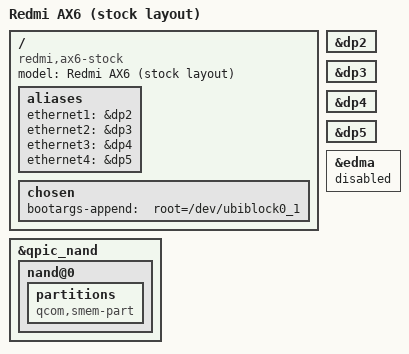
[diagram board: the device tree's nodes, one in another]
// SPDX-License-Identifier: GPL-2.0-or-later OR MIT

/dts-v1/;

#include "ipq8071-ax6.dts"

/ {
	model = "Redmi AX6 (stock layout)";
	compatible = "redmi,ax6-stock", "qcom,ipq8074";

	aliases {
		ethernet1 = &dp2;
		ethernet2 = &dp3;
		ethernet3 = &dp4;
		ethernet4 = &dp5;
	};

	chosen {
		bootargs-append = " root=/dev/ubiblock0_1";
	};
};

&qpic_nand {
	/delete-node/ partitions;

	nand@0 {
		/delete-node/ partitions;

		partitions {
			compatible = "qcom,smem-part";
		};
	};
};

/*
 * Xiaomi and custom U-Boot builds patch the port MAC addresses through the
 * ethernet aliases above.  Some custom builds also replace the SMEM partition
 * nodes in the live FDT, which would leave inherited nvmem phandles dangling.
 */
&dp2 {
	/delete-property/ nvmem-cells;
	/delete-property/ nvmem-cell-names;
};

&dp3 {
	/delete-property/ nvmem-cells;
	/delete-property/ nvmem-cell-names;
};

&dp4 {
	/delete-property/ nvmem-cells;
	/delete-property/ nvmem-cell-names;
};

&dp5 {
	/delete-property/ nvmem-cells;
	/delete-property/ nvmem-cell-names;
};

/*
 * The legacy Linux qcom,edma node is not the AX6 NSS-DP data plane.
 * It has no driver built and leaves the GCC reset/clock consumer unresolved,
 * producing "sync_state() pending due to 3ab00000.edma". NSS-DP owns the
 * hardware; keep the unused Linux node disabled.
 */
&edma {
	status = "disabled";
};
